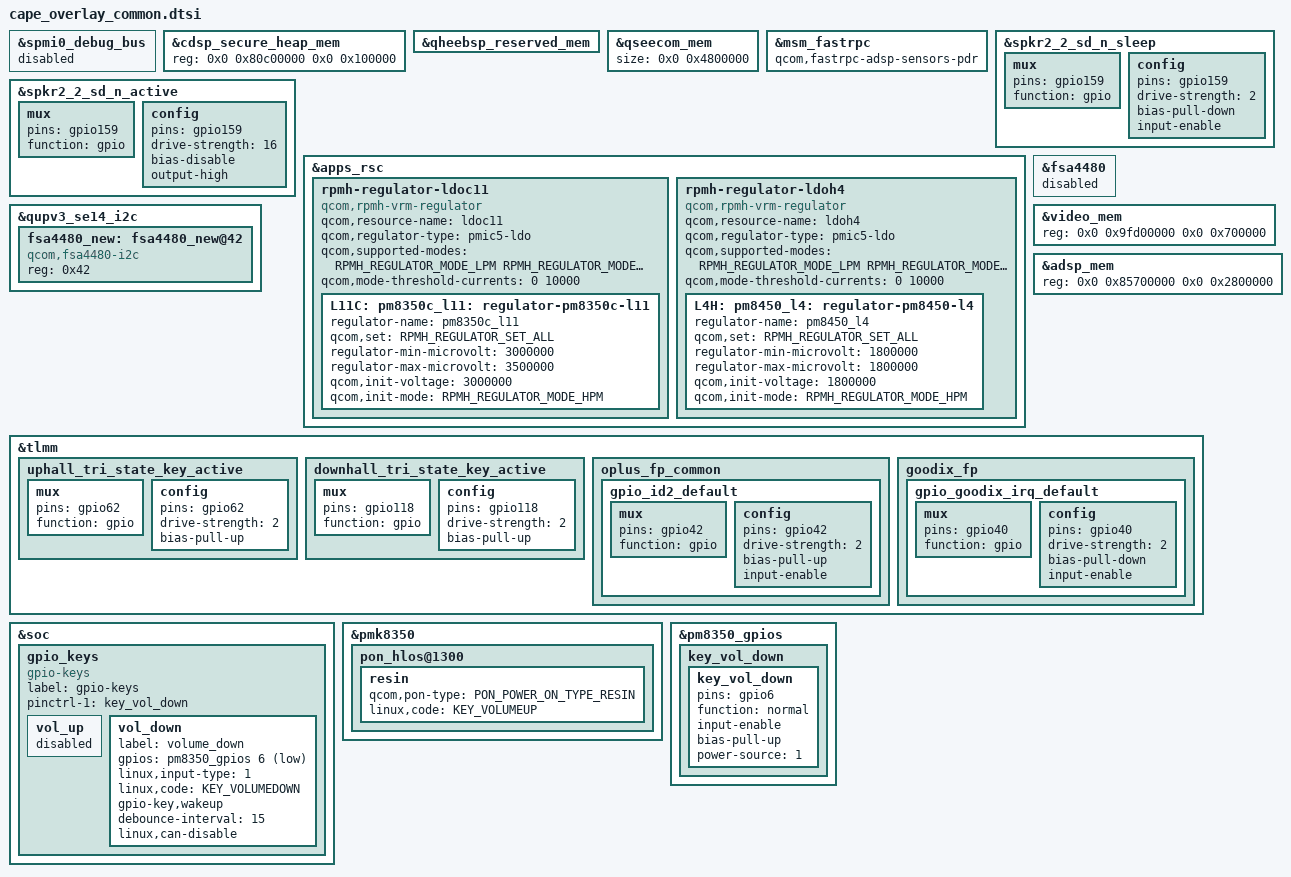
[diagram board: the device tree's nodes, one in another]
#include <dt-bindings/regulator/qcom,rpmh-regulator-levels.h>

#include "../qcom/cape-mtp.dtsi"
#include "../qcom/waipio-pm8010-spmi.dtsi"

&spmi0_debug_bus {
	status = "disabled";
};

&cdsp_secure_heap_mem {
	reg = <0x0 0x80c00000 0x0 0x100000>;
};

&qheebsp_reserved_mem {
	/delete-property/ reg;
};

&qseecom_mem {
	size = <0x0 0x4800000>;
};

&msm_fastrpc {
	/delete-property/ qcom,fastrpc-slpi-sensors-pdr;
	qcom,fastrpc-adsp-sensors-pdr;
};

/* GPIO 3 is the display LCD reset pin, which is occupied by audio. */
/* Therefore, gpio3 is modified to gpio159. */
/* Gpio159 is not used in the 8475T baseline. */
&spkr2_2_sd_n_sleep {
	mux {
		pins = "gpio159";
		function = "gpio";
	};

	config {
		pins = "gpio159";
		drive-strength = <2>;   /* 2 mA */
		bias-pull-down;
		input-enable;
	};
};

&spkr2_2_sd_n_active {
	mux {
		pins = "gpio159";
		function = "gpio";
	};

	config {
		pins = "gpio159";
		drive-strength = <16>;   /* 16 mA */
		bias-disable;
		output-high;
	};
};


&apps_rsc {
	//#ifdef OPLUS_FEATURE_FINGERPRINT
	rpmh-regulator-ldoc11 {
		compatible = "qcom,rpmh-vrm-regulator";
		qcom,resource-name = "ldoc11";
		qcom,regulator-type = "pmic5-ldo";
		qcom,supported-modes =
			<RPMH_REGULATOR_MODE_LPM
			 RPMH_REGULATOR_MODE_HPM>;
		qcom,mode-threshold-currents = <0 10000>;
		L11C: pm8350c_l11: regulator-pm8350c-l11 {
			regulator-name = "pm8350c_l11";
			qcom,set = <RPMH_REGULATOR_SET_ALL>;
			regulator-min-microvolt = <3000000>;
			regulator-max-microvolt = <3500000>;
			qcom,init-voltage = <3000000>;
			qcom,init-mode = <RPMH_REGULATOR_MODE_HPM>;
		};
	};
	//#endif /*OPLUS_FEATURE_FINGERPRINT*/
	rpmh-regulator-ldoh4 {
		compatible = "qcom,rpmh-vrm-regulator";
		qcom,resource-name = "ldoh4";
		qcom,regulator-type = "pmic5-ldo";
		qcom,supported-modes =
			<RPMH_REGULATOR_MODE_LPM
			 RPMH_REGULATOR_MODE_HPM>;
		qcom,mode-threshold-currents = <0 10000>;
		L4H: pm8450_l4: regulator-pm8450-l4 {
			regulator-name = "pm8450_l4";
			qcom,set = <RPMH_REGULATOR_SET_ALL>;
			regulator-min-microvolt = <1800000>;
			regulator-max-microvolt = <1800000>;
			qcom,init-voltage = <1800000>;
			qcom,init-mode = <RPMH_REGULATOR_MODE_HPM>;
		};
	};
	//#endif /*OPLUS_FEATURE_TP_BASIC*/
};

/* #ifdef OPLUS_ARCH_EXTENDS */
&fsa4480 {
	status = "disabled";
};

&qupv3_se14_i2c {
	status = "ok";
	fsa4480_new: fsa4480_new@42 {
		status = "ok";
		compatible = "qcom,fsa4480-i2c";
		reg = <0x42>;
	};
};
/* OPLUS_ARCH_EXTENDS */

/* #ifdef OPLUS_ARCH_EXTENDS */
&video_mem {
	reg = <0x0 0x9fd00000 0x0 0x700000>;
};

&adsp_mem {
	reg = <0x0 0x85700000 0x0 0x2800000>;
};
/* OPLUS_ARCH_EXTENDS */

//cape-pinctrl.dtsi
&tlmm {
	uphall_tri_state_key_active: uphall_tri_state_key_active {
		mux {
			pins = "gpio62";
			function = "gpio";
		};
		config {
			pins = "gpio62";
			drive-strength = <2>;
			bias-pull-up;
		};
	};

	downhall_tri_state_key_active: downhall_tri_state_key_active {
		mux {
			pins = "gpio118";
			function = "gpio";
		};
		config {
			pins = "gpio118";
			drive-strength = <2>;
			bias-pull-up;
		};
	};
//#endif /*OPLUS_FEATURE_TP_BASIC*/

	//#ifdef OPLUS_FEATURE_FINGERPRINT
	oplus_fp_common{
		gpio_id2_default: gpio_id2_default {
			mux {
				pins = "gpio42";
				function = "gpio";
			};
			config {
				pins = "gpio42";
				drive-strength = <2>;
				bias-pull-up;
				input-enable;
			};
		};
	};
	goodix_fp{
		gpio_goodix_irq_default: gpio_goodix_irq_default {
			mux {
				pins = "gpio40";
				function = "gpio";
			};
			config {
				pins = "gpio40";
				drive-strength = <2>;
				bias-pull-down;
				input-enable;
			};
		};
	};
	//#endif /*OPLUS_FEATURE_FINGERPRINT*/
};

&soc {
	/*#ifdef OPLUS_FEATURE_TP_BASIC*/
	gpio_keys {
		compatible = "gpio-keys";
		label = "gpio-keys";

		pinctrl-names = "default";
		pinctrl-1 = <&key_vol_down>;

		vol_up {
			status="disabled";
		};

		vol_down {
			label = "volume_down";
			gpios = <&pm8350_gpios 6 GPIO_ACTIVE_LOW>;
			linux,input-type = <1>;
			linux,code = <KEY_VOLUMEDOWN>;
			gpio-key,wakeup;
			debounce-interval = <15>;
			linux,can-disable;
		};
	};
	/*#endif OPLUS_FEATURE_TP_BASIC*/
};

/*#ifdef OPLUS_FEATURE_TP_BASIC*/
&pmk8350 {
	pon_hlos@1300 {
		resin {
		    qcom,pon-type = <PON_POWER_ON_TYPE_RESIN>;
		    linux,code = <KEY_VOLUMEUP>;
		};
	};
};

&pm8350_gpios {
	key_vol_down {
		key_vol_down: key_vol_down {
			pins = "gpio6";
			function = "normal";
			input-enable;
			bias-pull-up;
			power-source = <1>;
		};
	};
};
/*#endif OPLUS_FEATURE_TP_BASIC*/
